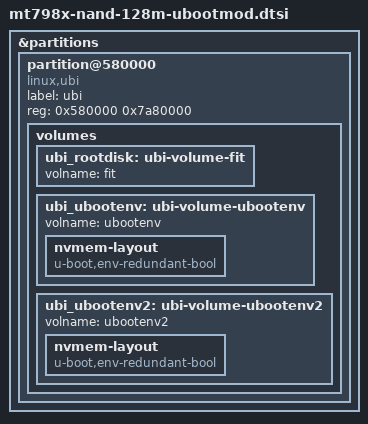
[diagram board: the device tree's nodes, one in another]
// SPDX-License-Identifier: (GPL-2.0 OR MIT)

&partitions {
	partition@580000 {
		label = "ubi";
		compatible = "linux,ubi";
		reg = <0x580000 0x7a80000>;
		volumes {
			ubi_rootdisk: ubi-volume-fit {
				volname = "fit";
			};

			ubi_ubootenv: ubi-volume-ubootenv {
				volname = "ubootenv";
			};

			ubi_ubootenv2: ubi-volume-ubootenv2 {
				volname = "ubootenv2";
			};
		};
	};
};

&ubi_ubootenv {
	nvmem-layout {
		compatible = "u-boot,env-redundant-bool";
	};
};

&ubi_ubootenv2 {
	nvmem-layout {
		compatible = "u-boot,env-redundant-bool";
	};
};
